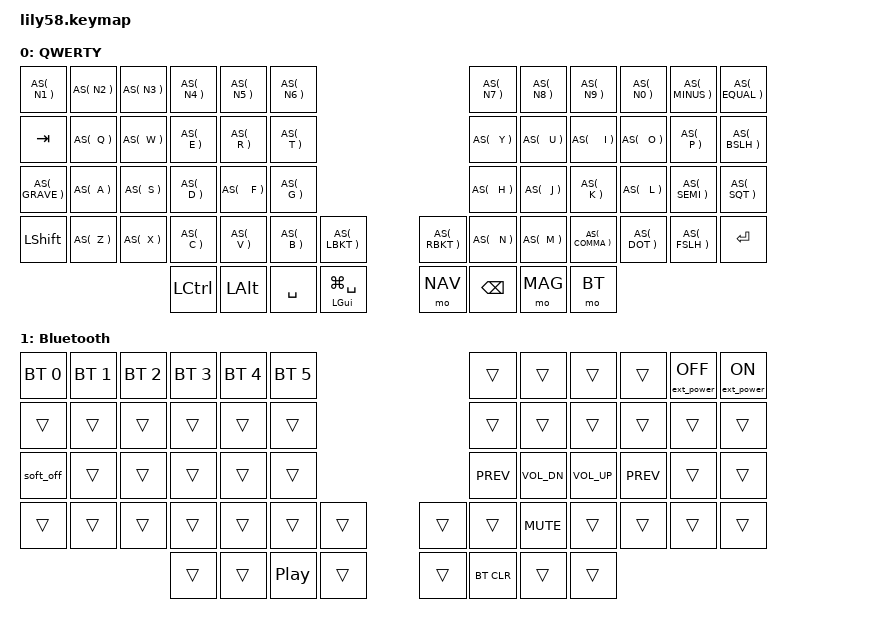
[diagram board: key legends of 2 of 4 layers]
/*
 * Copyright (c) 2020 The ZMK Contributors
 *
 * SPDX-License-Identifier: MIT
 */

#include <behaviors.dtsi>
#include <dt-bindings/zmk/keys.h>
#include <dt-bindings/zmk/bt.h>
#include <dt-bindings/zmk/ext_power.h>

#define DFLT    0
#define BT      1
#define NAV     2
#define MAG     3

#define AS(CODE) &as_##CODE CODE CODE  // Autoshift

#define DEFINE_AUTOSHIFT(CODE) \
/ { \
	macros { \
		ZMK_MACRO( \
			shift_##CODE, \
			wait-ms = <0>; \
			tap-ms = <0>; \
			bindings = <&macro_tap &kp LS(CODE)>; \
		) \
	}; \
    behaviors { \
    	as_##CODE: autoshift_##CODE { \
			compatible = "zmk,behavior-hold-tap"; \
			flavor = "tap-preferred"; \
			tapping-term-ms = <200>; \
			quick-tap-ms = <300>; \
			#binding-cells = <2>; \
			bindings = <&shift_##CODE>, <&kp>; \
		}; \
    }; \
};

// Define the macros needed for autoshifting
DEFINE_AUTOSHIFT(GRAVE) \
DEFINE_AUTOSHIFT(N1) \
DEFINE_AUTOSHIFT(N2) \
DEFINE_AUTOSHIFT(N3) \
DEFINE_AUTOSHIFT(N4) \
DEFINE_AUTOSHIFT(N5) \
DEFINE_AUTOSHIFT(N6) \
DEFINE_AUTOSHIFT(N7) \
DEFINE_AUTOSHIFT(N8) \
DEFINE_AUTOSHIFT(N9) \
DEFINE_AUTOSHIFT(N0) \
DEFINE_AUTOSHIFT(MINUS) \
DEFINE_AUTOSHIFT(EQUAL) \
DEFINE_AUTOSHIFT(Q) \
DEFINE_AUTOSHIFT(W) \
DEFINE_AUTOSHIFT(E) \
DEFINE_AUTOSHIFT(R) \
DEFINE_AUTOSHIFT(T) \
DEFINE_AUTOSHIFT(SQT) \
DEFINE_AUTOSHIFT(Y) \
DEFINE_AUTOSHIFT(U) \
DEFINE_AUTOSHIFT(I) \
DEFINE_AUTOSHIFT(O) \
DEFINE_AUTOSHIFT(P) \
DEFINE_AUTOSHIFT(A) \
DEFINE_AUTOSHIFT(S) \
DEFINE_AUTOSHIFT(D) \
DEFINE_AUTOSHIFT(F) \
DEFINE_AUTOSHIFT(G) \
DEFINE_AUTOSHIFT(LBKT) \
DEFINE_AUTOSHIFT(RBKT) \
DEFINE_AUTOSHIFT(H) \
DEFINE_AUTOSHIFT(J) \
DEFINE_AUTOSHIFT(K) \
DEFINE_AUTOSHIFT(L) \
DEFINE_AUTOSHIFT(SEMI) \
DEFINE_AUTOSHIFT(Z) \
DEFINE_AUTOSHIFT(X) \
DEFINE_AUTOSHIFT(C) \
DEFINE_AUTOSHIFT(V) \
DEFINE_AUTOSHIFT(B) \
DEFINE_AUTOSHIFT(N) \
DEFINE_AUTOSHIFT(M) \
DEFINE_AUTOSHIFT(COMMA) \
DEFINE_AUTOSHIFT(DOT) \
DEFINE_AUTOSHIFT(SLASH) \
DEFINE_AUTOSHIFT(BSLH) \
DEFINE_AUTOSHIFT(FSLH)

/ {

    keymap {
        compatible = "zmk,keymap";

        default_layer {
            display-name = "QWERTY";
// ------------------------------------------------------------------------------------------------------------
// |   1   |  2  |  3  |  4   |  5   |  6    |                   |  7   |  8    |  9    |  0   |   -   |   =   |
// |  TAB  |  Q  |  W  |  E   |  R   |  T    |                   |  Y   |  U    |  I    |  O   |   P   |   -   |
// |  ESC  |  A  |  S  |  D   |  F   |  G    |                   |  H   |  J    |  K    |  L   |   ;   |   '   |
// | SHIFT |  Z  |  X  |  C   |  V   |  B    |   "["  |  |  "]"  |  N   |  M    |  ,    |  .   |   /   | SHIFT |
//                     | CTRL | ALT  | SPACE |  GUI   |  |  NAV  | BSPC | MAG   | BT    |
            bindings = <
AS(    N1 ) AS( N2 ) AS( N3 ) AS(    N4 ) AS(   N5 ) AS(    N6 )                       AS(  N7 ) AS(  N8 ) AS(    N9 ) AS(  N0 ) AS( MINUS ) AS( EQUAL )
&kp   TAB   AS(  Q ) AS(  W ) AS(     E ) AS(    R ) AS(     T )                       AS(   Y ) AS(   U ) AS(     I ) AS(   O ) AS(     P ) AS(  BSLH )
AS( GRAVE ) AS(  A ) AS(  S ) AS(     D ) AS(    F ) AS(     G )                       AS(   H ) AS(   J ) AS(     K ) AS(   L ) AS(  SEMI ) AS(   SQT )
&kp LSHFT   AS(  Z ) AS(  X ) AS(     C ) AS(    V ) AS(     B ) AS( LBKT ) AS( RBKT ) AS(   N )  AS(  M ) AS( COMMA ) AS( DOT ) AS(  FSLH ) &kp   RET 

                &kp LCTRL &kp LALT &kp SPACE &mt LGUI LG(SPACE)  &mo NAV &kp BSPC &mo MAG &mo BT
            >;
        };

        bluetooth_layer {
            display-name = "Bluetooth";
            bindings = <
&bt BT_SEL 0 &bt BT_SEL 1 &bt BT_SEL 2 &bt BT_SEL 3 &bt BT_SEL 4 &bt BT_SEL 5                    &trans     &trans       &trans       &trans     &ext_power EP_OFF &ext_power EP_ON
&trans       &trans       &trans       &trans       &trans       &trans                          &trans     &trans       &trans       &trans     &trans            &trans
&soft_off    &trans       &trans       &trans       &trans       &trans                          &kp C_PREV &kp C_VOL_DN &kp C_VOL_UP &kp C_PREV &trans            &trans
&trans       &trans       &trans       &trans       &trans       &trans        &trans &trans     &trans     &kp C_MUTE   &trans       &trans     &trans            &trans
                                                        &trans &trans &kp C_PP &trans &trans &bt BT_CLR &trans &trans
            >;
        };

        navigation_layer {
            display-name = "Navigation";
            bindings = <
&trans      &trans &trans &trans &trans &trans               &trans   &trans   &trans &trans    &trans &trans
&trans      &trans &trans &trans &trans &trans               &trans   &trans   &trans &trans    &trans &trans
&kp ESC     &trans &trans &trans &trans &trans               &kp LEFT &kp DOWN &kp UP &kp RIGHT &trans &trans
&trans      &trans &trans &trans &trans &trans &trans &trans &trans   &trans   &trans &trans    &trans &trans
                             &trans &trans &trans &trans &kp LC(LALT)   &trans
            >;
        };

        magnet_layer {
            display-name = "Magnet";
            bindings = <
&trans &trans &trans &trans         &trans         &trans                         &trans           &trans           &trans         &trans            &trans &trans
&trans &trans &trans &kp LC(LA(E))  &trans         &kp LC(LA(T))                  &trans           &trans           &trans         &trans            &trans &trans
&trans &trans &trans &kp LC(LA(D))  &kp LC(LA(F))  &kp LC(LA(G))                  &kp LC(LA(LEFT)) &kp LC(LA(DOWN)) &kp LC(LA(UP)) &kp LC(LA(RIGHT)) &trans &trans
&trans &trans &trans &kp LC(LA(C))  &trans         &trans         &trans  &trans  &trans           &trans           &trans         &trans            &trans &kp LC(LA(RET))
                                                   &trans  &trans &trans  &trans  &kp LC(LALT)     &trans
            >;
        };
    };
};
